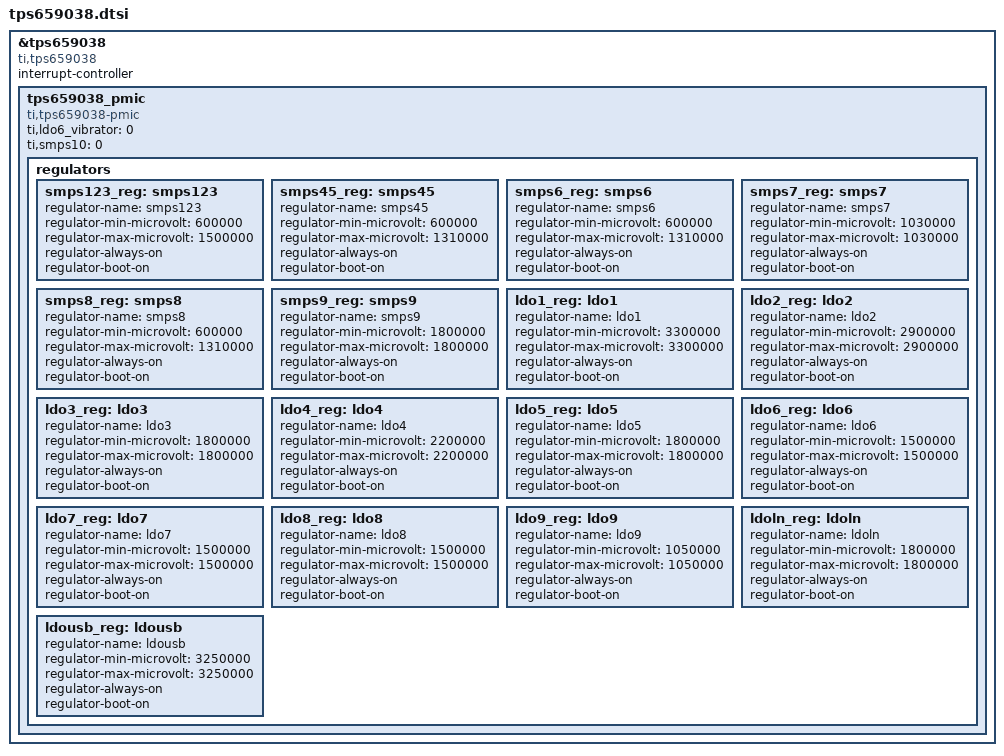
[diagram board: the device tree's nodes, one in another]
/*
 * Copyright (C) 2013 Texas Instruments Incorporated - http://www.ti.com/
 *
 * This program is free software; you can redistribute it and/or modify
 * it under the terms of the GNU General Public License version 2 as
 * published by the Free Software Foundation.
 * Based on "omap4.dtsi"
 */

/*
 * TPS659038 is an Integrated Power Management Chip from Texas Instruments
 * Data Manual - TPS659039-Q1 POWER MANAGEMENT UNIT (PMU) FOR PROCESSOR Data Manual
 * Register Manual - TPS659038/39-Q1 Functional Register Descriptions.
 */

&tps659038 {
	compatible = "ti,tps659038";
	interrupt-controller;
	#interrupt-cells = <2>;

	tps659038_pmic {
		compatible = "ti,tps659038-pmic";
		ti,ldo6_vibrator = <0>;
		ti,smps10 = <0>;

		regulators {
			smps123_reg: smps123 {
				regulator-name = "smps123";
				regulator-min-microvolt = < 600000>;
				regulator-max-microvolt = <1500000>;
				regulator-always-on;
				regulator-boot-on;
			};

			smps45_reg: smps45 {
				regulator-name = "smps45";
				regulator-min-microvolt = < 600000>;
				regulator-max-microvolt = <1310000>;
				regulator-always-on;
				regulator-boot-on;
			};

			smps6_reg: smps6 {
				regulator-name = "smps6";
				regulator-min-microvolt = <600000>;
				regulator-max-microvolt = <1310000>;
				regulator-always-on;
				regulator-boot-on;
			};

			smps7_reg: smps7 {
				regulator-name = "smps7";
				regulator-min-microvolt = <1030000>;
				regulator-max-microvolt = <1030000>;
				regulator-always-on;
				regulator-boot-on;
			};

			smps8_reg: smps8 {
				regulator-name = "smps8";
				regulator-min-microvolt = < 600000>;
				regulator-max-microvolt = <1310000>;
				regulator-always-on;
				regulator-boot-on;
			};

			smps9_reg: smps9 {
				regulator-name = "smps9";
				regulator-min-microvolt = <1800000>;
				regulator-max-microvolt = <1800000>;
				regulator-always-on;
				regulator-boot-on;
			};

			ldo1_reg: ldo1 {
				regulator-name = "ldo1";
				regulator-min-microvolt = <3300000>;
				regulator-max-microvolt = <3300000>;
				regulator-always-on;
				regulator-boot-on;
			};

			ldo2_reg: ldo2 {
				regulator-name = "ldo2";
				regulator-min-microvolt = <2900000>;
				regulator-max-microvolt = <2900000>;
				regulator-always-on;
				regulator-boot-on;
			};

			ldo3_reg: ldo3 {
				regulator-name = "ldo3";
				regulator-min-microvolt = <1800000>;
				regulator-max-microvolt = <1800000>;
				regulator-always-on;
				regulator-boot-on;
			};

			ldo4_reg: ldo4 {
				regulator-name = "ldo4";
				regulator-min-microvolt = <2200000>;
				regulator-max-microvolt = <2200000>;
				regulator-always-on;
				regulator-boot-on;
			};

			ldo5_reg: ldo5 {
				regulator-name = "ldo5";
				regulator-min-microvolt = <1800000>;
				regulator-max-microvolt = <1800000>;
				regulator-always-on;
				regulator-boot-on;
			};

			ldo6_reg: ldo6 {
				regulator-name = "ldo6";
				regulator-min-microvolt = <1500000>;
				regulator-max-microvolt = <1500000>;
				regulator-always-on;
				regulator-boot-on;
			};

			ldo7_reg: ldo7 {
				regulator-name = "ldo7";
				regulator-min-microvolt = <1500000>;
				regulator-max-microvolt = <1500000>;
				regulator-always-on;
				regulator-boot-on;
			};

			ldo8_reg: ldo8 {
				regulator-name = "ldo8";
				regulator-min-microvolt = <1500000>;
				regulator-max-microvolt = <1500000>;
				regulator-always-on;
				regulator-boot-on;
			};

			ldo9_reg: ldo9 {
				regulator-name = "ldo9";
				regulator-min-microvolt = <1050000>;
				regulator-max-microvolt = <1050000>;
				regulator-always-on;
				regulator-boot-on;
			};

			ldoln_reg: ldoln {
				regulator-name = "ldoln";
				regulator-min-microvolt = <1800000>;
				regulator-max-microvolt = <1800000>;
				regulator-always-on;
				regulator-boot-on;
			};

			ldousb_reg: ldousb {
				regulator-name = "ldousb";
				regulator-min-microvolt = <3250000>;
				regulator-max-microvolt = <3250000>;
				regulator-always-on;
				regulator-boot-on;
			};
		};
	};
};
